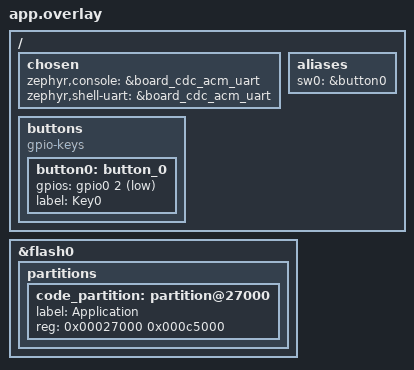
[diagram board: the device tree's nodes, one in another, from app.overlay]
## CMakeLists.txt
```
# Copyright (c) 2026
# SPDX-License-Identifier: MIT
#
# Out-of-tree NCS/Zephyr application for Pro Micro nRF52840 Unifying tests.
# Build from an nRF Connect SDK workspace:
#   west build -b promicro_nrf52840/nrf52840/uf2 <path-to>/examples/promicro_nrf52840

cmake_minimum_required(VERSION 3.20.0)

# Use the SuperMini S140 v7 UF2 + SoftDevice flash map.
set(PM_STATIC_YML_FILE ${CMAKE_CURRENT_SOURCE_DIR}/pm_static.yml CACHE FILEPATH
    "Static partition map for SuperMini S140 v7 UF2" FORCE)

find_package(Zephyr REQUIRED HINTS $ENV{ZEPHYR_BASE})
project(promicro_unifying)

set(UNIFYING_SRC_DIR ${CMAKE_CURRENT_SOURCE_DIR}/../../src)

target_include_directories(app PRIVATE
  ${CMAKE_CURRENT_SOURCE_DIR}/src
  ${UNIFYING_SRC_DIR}
)

target_sources(app PRIVATE
  src/main.c
  src/radio_esb.c
  src/usb_cli.c
  src/persist.c
  src/keymap.c
  src/key_gpio.c
  ${UNIFYING_SRC_DIR}/unifying.c
  ${UNIFYING_SRC_DIR}/unifying_data.c
  ${UNIFYING_SRC_DIR}/unifying_state.c
  ${UNIFYING_SRC_DIR}/unifying_buffer.c
  ${UNIFYING_SRC_DIR}/unifying_utils.c
  ${UNIFYING_SRC_DIR}/unifying_const.c
  ${UNIFYING_SRC_DIR}/unifying_error.c
  ${UNIFYING_SRC_DIR}/aes.c
)
```

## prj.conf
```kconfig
# --- Unifying RF via Nordic ESB (nRF Connect SDK) ---
CONFIG_ESB=y
CONFIG_ESB_MAX_PAYLOAD_LENGTH=32
CONFIG_BT=n

# SuperMini S140 v7 bootloader: emit UF2 and keep the SoftDevice gap
CONFIG_BUILD_OUTPUT_UF2=y
CONFIG_BUILD_OUTPUT_HEX=y

# --- Heap for unifying ring buffers / payloads (malloc) ---
CONFIG_HEAP_MEM_POOL_SIZE=8192
CONFIG_COMMON_LIBC_MALLOC=y

# --- Timing / entropy ---
CONFIG_ENTROPY_GENERATOR=y
CONFIG_PRINTK=y
CONFIG_STDOUT_CONSOLE=y
CONFIG_LOG=y
CONFIG_LOG_DEFAULT_LEVEL=3

# --- GPIO LED ---
CONFIG_GPIO=y

# --- Flash / NVS for pairing credentials ---
CONFIG_FLASH=y
CONFIG_FLASH_MAP=y
CONFIG_FLASH_PAGE_LAYOUT=y
CONFIG_NVS=y
CONFIG_MPU_ALLOW_FLASH_WRITE=y

# --- USB CDC ACM console ---
CONFIG_SERIAL=y
CONFIG_CONSOLE=y
CONFIG_UART_CONSOLE=y
CONFIG_UART_LINE_CTRL=y
CONFIG_USB_DEVICE_STACK_NEXT=y
CONFIG_CDC_ACM_SERIAL_INITIALIZE_AT_BOOT=y
CONFIG_USB_DEVICE_PRODUCT="ProMicro Unifying"
CONFIG_USB_DEVICE_VID=0x1915
CONFIG_USB_DEVICE_PID=0x520F

# Ring buffer for UART RX line assembly
CONFIG_RING_BUFFER=y

# Main stack for pair/connect loops
CONFIG_MAIN_STACK_SIZE=4096
CONFIG_SYSTEM_WORKQUEUE_STACK_SIZE=2048
```

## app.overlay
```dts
/ {
	chosen {
		zephyr,console = &board_cdc_acm_uart;
		zephyr,shell-uart = &board_cdc_acm_uart;
	};

	/*
	 * 测试按键：P0.02 (Pro Micro D19) 对 GND，内部上拉，按下为低有效。
	 * 按下后：休眠则唤醒重连，并发送键 'a'。可按实际矩阵改引脚。
	 */
	buttons {
		compatible = "gpio-keys";
		button0: button_0 {
			gpios = <&gpio0 2 (GPIO_PULL_UP | GPIO_ACTIVE_LOW)>;
			label = "Key0";
		};
	};

	aliases {
		sw0 = &button0;
	};
};

/* SuperMini uses SoftDevice S140 v7.3.0; replace the board's v6 code node. */
&flash0 {
	partitions {
		/delete-node/ partition@26000;

		code_partition: partition@27000 {
			label = "Application";
			reg = <0x00027000 0x000c5000>;
		};
	};
};
```

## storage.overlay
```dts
/*
 * Optional storage partition for boards that lack one in DTS.
 * nRF Connect SDK Partition Manager usually provides storage_partition
 * automatically when CONFIG_NVS=y; this overlay is a fallback for
 * vanilla Zephyr builds of promicro_nrf52840 / nice_nano class boards.
 *
 * If your build already defines storage_partition, west may warn about
 * duplicate labels — remove this file or the partition block in that case.
 */

&flash0 {
	partitions {
		compatible = "fixed-partitions";
		#address-cells = <1>;
		#size-cells = <1>;

		/* Keep bootloader / app layout from board; only ensure a storage label exists.
		 * 8 KiB at end of 1 MiB flash (adjust if your UF2 layout differs).
		 */
		storage_partition: partition@f8000 {
			label = "storage";
			reg = <0x000f8000 0x00008000>;
		};
	};
};
```

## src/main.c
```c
/*!
 * \file main.c
 * \brief Pro Micro nRF52840 Unifying：异步唤醒发键 + USB/RADIO 休眠。
 */

#include <string.h>

#include <zephyr/device.h>
#include <zephyr/drivers/gpio.h>
#include <zephyr/kernel.h>
#include <zephyr/logging/log.h>
#include <zephyr/random/random.h>
#include <zephyr/sys/util.h>

#include "app_ctx.h"
#include "key_gpio.h"
#include "keymap.h"
#include "persist.h"
#include "radio_esb.h"
#include "usb_cli.h"
#include "unifying.h"

LOG_MODULE_REGISTER(main, CONFIG_LOG_DEFAULT_LEVEL);

#define TRANSMIT_BUFFER_SIZE 8
#define RECEIVE_BUFFER_SIZE 8
#define DEVICE_NAME "ProMicroKB"
#define DEVICE_PRODUCT_ID 0x1025
#define DEVICE_SERIAL 0xA58094B6u
#define DEVICE_TYPE 0x0147
#define CAPABILITIES 0x1E40

#define BOOT_PAIR_WINDOW_MS (20 * 1000)
#define IDLE_SLEEP_MS (60 * 1000)
#define BOOT_PAIR_RETRY_MS 2000
#define KEY_RELEASE_GAP_MS 20

#if DT_NODE_HAS_STATUS(DT_ALIAS(led0), okay)
static const struct gpio_dt_spec led = GPIO_DT_SPEC_GET(DT_ALIAS(led0), gpios);
static bool led_ready;
#else
static bool led_ready;
#endif

static struct app_ctx g_ctx;

const char *app_mode_name(enum app_mode mode)
{
	switch (mode) {
	case APP_MODE_IDLE:
		return "idle";
	case APP_MODE_PAIRING:
		return "pairing";
	case APP_MODE_CONNECTED:
		return "connected";
	case APP_MODE_SLEEPING:
		return "sleeping";
	default:
		return "unknown";
	}
}

void app_note_activity(struct app_ctx *ctx)
{
	if (ctx != NULL) {
		ctx->last_activity_ms = k_uptime_get();
	}
}

void app_stop_boot_try(struct app_ctx *ctx)
{
	if (ctx != NULL) {
		ctx->boot_trying = false;
	}
}

void app_start_boot_pair(struct app_ctx *ctx)
{
	if (ctx == NULL) {
		return;
	}

	ctx->boot_trying = true;
	ctx->boot_deadline_ms = k_uptime_get() + BOOT_PAIR_WINDOW_MS;
	ctx->next_boot_attempt_ms = 0;
	LOG_INF("Boot pair window %d ms", BOOT_PAIR_WINDOW_MS);
}

bool app_rf_busy(const struct app_ctx *ctx)
{
	return ctx != NULL && ctx->rf_phase != APP_RF_IDLE;
}

static void led_set(bool on)
{
#if DT_NODE_HAS_STATUS(DT_ALIAS(led0), okay)
	if (!led_ready) {
		return;
	}

	gpio_pin_set_dt(&led, on ? 1 : 0);
#else
	ARG_UNUSED(on);
#endif
}

static void led_init(void)
{
#if DT_NODE_HAS_STATUS(DT_ALIAS(led0), okay)
	if (!device_is_ready(led.port)) {
		LOG_WRN("LED not ready");
		return;
	}

	if (gpio_pin_configure_dt(&led, GPIO_OUTPUT_INACTIVE) != 0) {
		LOG_WRN("LED configure failed");
		return;
	}

	led_ready = true;
#else
	LOG_WRN("No led0 alias");
#endif
}

static uint32_t random_u32(void)
{
	return sys_rand32_get();
}

static void save_credentials(struct app_ctx *ctx)
{
	struct persist_credentials cred;

	memcpy(cred.address, ctx->address, UNIFYING_ADDRESS_LEN);
	memcpy(cred.aes_key, ctx->aes_key, UNIFYING_AES_BLOCK_LEN);
	cred.aes_counter = ctx->aes_counter;
	if (persist_save(&cred) == 0) {
		ctx->has_credentials = true;
	}
}

static void sync_counter_from_state(struct app_ctx *ctx)
{
	ctx->aes_counter = ctx->state.aes_counter;
}

static void state_bind(struct app_ctx *ctx)
{
	unifying_state_init(&ctx->state,
			    &ctx->interface,
			    ctx->transmit_buffer,
			    ctx->receive_buffer,
			    ctx->address,
			    ctx->aes_key,
			    ctx->aes_counter,
			    UNIFYING_DEFAULT_TIMEOUT_KEYBOARD,
			    radio_esb_last_channel());
}

static enum unifying_error rf_prepare_radio(struct app_ctx *ctx)
{
	uint8_t ch;

	if (ctx->usb_suspended) {
		if (usb_cli_resume() != 0) {
			return UNIFYING_ERROR;
		}
		ctx->usb_suspended = false;
	}

	if (radio_esb_is_sleeping()) {
		if (radio_esb_wake() != 0) {
			return UNIFYING_ERROR;
		}
	}

	if (ctx->interface.set_address(ctx->address) != 0) {
		return UNIFYING_SET_ADDRESS_ERROR;
	}

	ch = radio_esb_last_channel();
	if (ctx->interface.set_channel(ch) != 0) {
		return UNIFYING_SET_CHANNEL_ERROR;
	}

	ctx->state.channel = ch;
	unifying_state_buffers_clear(&ctx->state);
	ctx->state.next_transmit = 0;
	ctx->state.previous_transmit = 0;

	LOG_INF("RF start on channel %u (last)", ch);
	return unifying_connect_begin(&ctx->state);
}

static void rf_finish_fail(struct app_ctx *ctx, enum unifying_error err)
{
	ctx->last_error = err;
	ctx->rf_phase = APP_RF_IDLE;
	ctx->key_pending = false;

	if (ctx->boot_connect_pending) {
		ctx->boot_connect_pending = false;
		LOG_WRN("Boot reconnect failed (%s) → pair window",
			unifying_get_error_name(err));
		app_start_boot_pair(ctx);
		return;
	}

	if (ctx->keep_boot_pair_on_fail && ctx->boot_trying) {
		LOG_WRN("Key reconnect failed (%s), continue pairing",
			unifying_get_error_name(err));
		ctx->keep_boot_pair_on_fail = false;
		ctx->mode = APP_MODE_IDLE;
		led_set(false);
		return;
	}

	ctx->keep_boot_pair_on_fail = false;
	ctx->mode = APP_MODE_IDLE;
	led_set(false);
}

static void rf_finish_connected(struct app_ctx *ctx)
{
	ctx->mode = APP_MODE_CONNECTED;
	led_set(true);
	app_note_activity(ctx);
	app_stop_boot_try(ctx);
	ctx->boot_connect_pending = false;
	ctx->keep_boot_pair_on_fail = false;
	ctx->rf_phase = APP_RF_IDLE;
	LOG_INF("Connected (ch=%u)", radio_esb_last_channel());
}

static enum unifying_error rf_start(struct app_ctx *ctx, bool with_key, const char *name)
{
	struct keymap_stroke stroke;

	if (app_rf_busy(ctx)) {
		return UNIFYING_ERROR;
	}

	if (!ctx->has_credentials && ctx->mode != APP_MODE_CONNECTED) {
		return UNIFYING_ERROR;
	}

	ctx->key_pending = with_key;
	ctx->keep_boot_pair_on_fail = ctx->boot_trying;
	ctx->connect_attempts = 0;
	ctx->press_attempts = 0;
	ctx->release_at_ms = 0;

	if (with_key) {
		if (name == NULL || name[0] == '\0') {
			return UNIFYING_ERROR;
		}
		if (!keymap_parse(name, &stroke)) {
			return UNIFYING_ERROR;
		}
		strncpy(ctx->key_name, name, sizeof(ctx->key_name) - 1);
		ctx->key_name[sizeof(ctx->key_name) - 1] = '\0';
		memcpy(ctx->pending_keys, stroke.keys, UNIFYING_KEYS_LEN);
		ctx->pending_modifiers = stroke.modifiers;
	} else {
		ctx->key_name[0] = '\0';
	}

	if (ctx->mode == APP_MODE_CONNECTED && with_key) {
		ctx->rf_phase = APP_RF_SEND_PRESS;
		return UNIFYING_SUCCESS;
	}

	ctx->rf_phase = APP_RF_WAKE_USB_RADIO;
	return UNIFYING_SUCCESS;
}

enum unifying_error app_key_request(struct app_ctx *ctx, const char *name)
{
	return rf_start(ctx, true, name);
}

enum unifying_error app_connect_request(struct app_ctx *ctx)
{
	if (!ctx->has_credentials) {
		return UNIFYING_ERROR;
	}

	return rf_start(ctx, false, NULL);
}

void app_rf_poll(struct app_ctx *ctx)
{
	enum unifying_error err;
	uint8_t release_keys[UNIFYING_KEYS_LEN] = {0};

	if (ctx == NULL || ctx->rf_phase == APP_RF_IDLE) {
		return;
	}

	switch (ctx->rf_phase) {
	case APP_RF_WAKE_USB_RADIO:
		err = rf_prepare_radio(ctx);
		if (err) {
			rf_finish_fail(ctx, err);
			return;
		}
		ctx->rf_phase = APP_RF_CONNECT_TRY;
		return;

	case APP_RF_CONNECT_TRY:
		err = unifying_loop(&ctx->state, true, true, false);
		if (!err) {
			if (ctx->key_pending) {
				ctx->rf_phase = APP_RF_SEND_PRESS;
			} else {
				rf_finish_connected(ctx);
			}
			return;
		}

		ctx->connect_attempts++;
		ctx->last_error = err;
		if (ctx->connect_attempts >= UNIFYING_CHANNELS_LEN) {
			unifying_state_buffers_clear(&ctx->state);
			rf_finish_fail(ctx, err);
			return;
		}
		/* 失败时协议库已 hop，wake 仍在队列，下圈再试 */
		return;

	case APP_RF_SEND_PRESS:
		led_set(true);
		err = unifying_encrypted_keystroke(&ctx->state,
						   ctx->pending_keys,
						   ctx->pending_modifiers);
		if (err == UNIFYING_TRANSMIT_ERROR) {
			ctx->press_attempts++;
			if (ctx->press_attempts >= UNIFYING_CHANNELS_LEN) {
				rf_finish_fail(ctx, err);
			}
			return;
		}
		if (err) {
			rf_finish_fail(ctx, err);
			return;
		}
		sync_counter_from_state(ctx);
		ctx->press_attempts = 0;
		ctx->release_at_ms = k_uptime_get() + KEY_RELEASE_GAP_MS;
		ctx->rf_phase = APP_RF_WAIT_RELEASE;
		ctx->mode = APP_MODE_CONNECTED;
		app_stop_boot_try(ctx);
		ctx->boot_connect_pending = false;
		ctx->keep_boot_pair_on_fail = false;
		return;

	case APP_RF_WAIT_RELEASE:
		if (k_uptime_get() < ctx->release_at_ms) {
			return;
		}
		ctx->rf_phase = APP_RF_SEND_RELEASE;
		ctx->press_attempts = 0;
		return;

	case APP_RF_SEND_RELEASE:
		err = unifying_encrypted_keystroke(&ctx->state, release_keys, 0);
		if (err == UNIFYING_TRANSMIT_ERROR) {
			ctx->press_attempts++;
			if (ctx->press_attempts >= UNIFYING_CHANNELS_LEN) {
				ctx->last_error = err;
				ctx->key_pending = false;
				app_note_activity(ctx);
				ctx->rf_phase = APP_RF_IDLE;
			}
			return;
		}
		if (err) {
			/* 按下已成功；松开失败仍算已连接 */
			ctx->last_error = err;
		} else {
			sync_counter_from_state(ctx);
			ctx->last_error = UNIFYING_SUCCESS;
		}
		ctx->key_pending = false;
		app_note_activity(ctx);
		ctx->rf_phase = APP_RF_IDLE;
		led_set(true);
		return;

	default:
		ctx->rf_phase = APP_RF_IDLE;
		return;
	}
}

enum unifying_error app_do_pair(struct app_ctx *ctx)
{
	enum unifying_error err;
	uint8_t id = (uint8_t)random_u32();
	uint32_t crypto = random_u32();
	const char *name = DEVICE_NAME;
	uint8_t name_length = (uint8_t)strlen(name);

	if (app_rf_busy(ctx)) {
		return UNIFYING_ERROR;
	}

	if (ctx->usb_suspended) {
		(void)usb_cli_resume();
		ctx->usb_suspended = false;
	}

	if (radio_esb_is_sleeping()) {
		if (radio_esb_wake() != 0) {
			return UNIFYING_ERROR;
		}
	}

	ctx->mode = APP_MODE_PAIRING;
	led_set(true);
	unifying_state_buffers_clear(&ctx->state);

	LOG_INF("Pairing as '%s' (len=%u) pid=0x%04x", name, name_length, DEVICE_PRODUCT_ID);

	err = unifying_pair(&ctx->state,
			    id,
			    DEVICE_PRODUCT_ID,
			    DEVICE_TYPE,
			    crypto,
			    DEVICE_SERIAL,
			    CAPABILITIES,
			    name,
			    name_length);
	if (err) {
		ctx->mode = APP_MODE_IDLE;
		led_set(false);
		return err;
	}

	sync_counter_from_state(ctx);
	save_credentials(ctx);
	ctx->mode = APP_MODE_CONNECTED;
	led_set(true);
	app_note_activity(ctx);
	LOG_INF("Paired OK ch=%u", radio_esb_last_channel());
	return UNIFYING_SUCCESS;
}

enum unifying_error app_do_sleep(struct app_ctx *ctx)
{
	app_stop_boot_try(ctx);
	ctx->boot_connect_pending = false;
	ctx->rf_phase = APP_RF_IDLE;
	ctx->key_pending = false;

	/* 休眠前刷一次 counter（平时只改 RAM） */
	if (ctx->has_credentials) {
		sync_counter_from_state(ctx);
		save_credentials(ctx);
	}

	unifying_state_buffers_clear(&ctx->state);
	radio_esb_sleep();

	if (!ctx->usb_suspended) {
		(void)usb_cli_suspend();
		ctx->usb_suspended = true;
	}

	key_gpio_clear_wake();

	ctx->mode = APP_MODE_SLEEPING;
	led_set(false);
	LOG_INF("Sleeping (RADIO+USB off, last_ch=%u)", radio_esb_last_channel());
	return UNIFYING_SUCCESS;
}

enum unifying_error app_do_wake(struct app_ctx *ctx)
{
	app_stop_boot_try(ctx);
	return app_connect_request(ctx);
}

enum unifying_error app_do_unpair(struct app_ctx *ctx)
{
	app_stop_boot_try(ctx);
	ctx->boot_connect_pending = false;
	ctx->rf_phase = APP_RF_IDLE;
	ctx->key_pending = false;
	(void)persist_clear();
	ctx->has_credentials = false;
	memset(ctx->address, 0, sizeof(ctx->address));
	memset(ctx->aes_key, 0, sizeof(ctx->aes_key));
	ctx->aes_counter = random_u32();
	unifying_state_buffers_clear(&ctx->state);

	if (ctx->usb_suspended) {
		(void)usb_cli_resume();
		ctx->usb_suspended = false;
	}

	ctx->mode = APP_MODE_IDLE;
	led_set(false);
	LOG_INF("Unpaired");
	return UNIFYING_SUCCESS;
}

void app_tick(struct app_ctx *ctx)
{
	enum unifying_error err;

	if (ctx->mode != APP_MODE_CONNECTED || app_rf_busy(ctx)) {
		return;
	}

	err = unifying_tick(&ctx->state);
	if (err && err != UNIFYING_TRANSMIT_ERROR) {
		ctx->last_error = err;
	}

	(void)radio_esb_current_channel();
}

void app_power_manage(struct app_ctx *ctx)
{
	int64_t now = k_uptime_get();

	if (app_rf_busy(ctx)) {
		return;
	}

	if (ctx->boot_trying) {
		if (ctx->mode == APP_MODE_CONNECTED) {
			app_stop_boot_try(ctx);
			app_note_activity(ctx);
			return;
		}

		if (now >= ctx->boot_deadline_ms) {
			LOG_WRN("Boot pair window expired → sleep");
			app_stop_boot_try(ctx);
			(void)app_do_sleep(ctx);
			return;
		}

		if (now < ctx->next_boot_attempt_ms) {
			return;
		}

		ctx->next_boot_attempt_ms = now + BOOT_PAIR_RETRY_MS;
		LOG_INF("Boot pair attempt (receiver must be in pairing mode)...");
		ctx->last_error = app_do_pair(ctx);

		if (ctx->mode == APP_MODE_CONNECTED) {
			app_stop_boot_try(ctx);
			app_note_activity(ctx);
		} else if (ctx->last_error) {
			LOG_WRN("Boot pair failed: %s",
				unifying_get_error_name(ctx->last_error));
		}
		return;
	}

	if (ctx->mode == APP_MODE_CONNECTED &&
	    (now - ctx->last_activity_ms) >= IDLE_SLEEP_MS) {
		LOG_INF("No key activity for %d ms → sleep", IDLE_SLEEP_MS);
		(void)app_do_sleep(ctx);
	}
}

int main(void)
{
	struct persist_credentials cred;
	int err;

	led_init();
	LOG_INF("ProMicro Unifying starting");

	err = usb_cli_init();
	if (err) {
		LOG_ERR("usb_cli_init: %d", err);
	}

	err = persist_init();
	if (err) {
		LOG_ERR("persist_init: %d", err);
	}

	err = radio_esb_init(&g_ctx.interface);
	if (err) {
		LOG_ERR("radio_esb_init: %d", err);
	}

	(void)key_gpio_init();

	g_ctx.transmit_buffer = unifying_ring_buffer_create(TRANSMIT_BUFFER_SIZE);
	g_ctx.receive_buffer = unifying_ring_buffer_create(RECEIVE_BUFFER_SIZE);
	if (g_ctx.transmit_buffer == NULL || g_ctx.receive_buffer == NULL) {
		LOG_ERR("ring buffer alloc failed");
		return 0;
	}

	g_ctx.aes_counter = random_u32();
	g_ctx.mode = APP_MODE_IDLE;
	g_ctx.last_error = UNIFYING_SUCCESS;
	g_ctx.last_activity_ms = k_uptime_get();
	g_ctx.rf_phase = APP_RF_IDLE;
	g_ctx.usb_suspended = false;
	g_ctx.boot_connect_pending = false;

	if (persist_load(&cred)) {
		memcpy(g_ctx.address, cred.address, UNIFYING_ADDRESS_LEN);
		memcpy(g_ctx.aes_key, cred.aes_key, UNIFYING_AES_BLOCK_LEN);
		g_ctx.aes_counter = cred.aes_counter;
		g_ctx.has_credentials = true;
		LOG_INF("Loaded credentials from NVS");
	} else {
		memset(g_ctx.address, 0, sizeof(g_ctx.address));
		memset(g_ctx.aes_key, 0, sizeof(g_ctx.aes_key));
		g_ctx.has_credentials = false;
		LOG_INF("No saved credentials");
	}

	state_bind(&g_ctx);

	g_ctx.boot_trying = false;
	if (g_ctx.has_credentials) {
		LOG_INF("Boot reconnect (async, last_ch=%u)...", radio_esb_last_channel());
		g_ctx.boot_connect_pending = true;
		g_ctx.last_error = app_connect_request(&g_ctx);
		if (g_ctx.last_error) {
			g_ctx.boot_connect_pending = false;
			app_start_boot_pair(&g_ctx);
		}
	} else {
		app_start_boot_pair(&g_ctx);
	}

	while (1) {
		if (g_ctx.mode == APP_MODE_SLEEPING && !app_rf_busy(&g_ctx)) {
			key_gpio_wait_wake();
		}

		usb_cli_poll(&g_ctx);
		key_gpio_service(&g_ctx);
		app_rf_poll(&g_ctx);
		app_power_manage(&g_ctx);
		app_tick(&g_ctx);

		if (g_ctx.mode != APP_MODE_SLEEPING || app_rf_busy(&g_ctx)) {
			k_msleep(1);
		}
	}

	return 0;
}
```

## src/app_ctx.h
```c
/*!
 * \file app_ctx.h
 * \brief 应用状态机与共享上下文。
 */

#ifndef APP_CTX_H
#define APP_CTX_H

#include <stdbool.h>
#include <stdint.h>

#include "persist.h"
#include "unifying.h"

#ifdef __cplusplus
extern "C" {
#endif

enum app_mode {
	APP_MODE_IDLE = 0,
	APP_MODE_PAIRING,
	APP_MODE_CONNECTED,
	APP_MODE_SLEEPING,
};

/*! 异步 RF / 发键状态机阶段。 */
enum app_rf_phase {
	APP_RF_IDLE = 0,
	APP_RF_WAKE_USB_RADIO,
	APP_RF_CONNECT_TRY,
	APP_RF_SEND_PRESS,
	APP_RF_WAIT_RELEASE,
	APP_RF_SEND_RELEASE,
};

#define APP_KEY_NAME_MAX 32

struct app_ctx {
	enum app_mode mode;
	bool has_credentials;
	enum unifying_error last_error;
	uint8_t address[UNIFYING_ADDRESS_LEN];
	uint8_t aes_key[UNIFYING_AES_BLOCK_LEN];
	uint32_t aes_counter;
	struct unifying_interface interface;
	struct unifying_ring_buffer *transmit_buffer;
	struct unifying_ring_buffer *receive_buffer;
	struct unifying_state state;

	/*! 上电配对窗口进行中。 */
	bool boot_trying;
	int64_t boot_deadline_ms;
	int64_t next_boot_attempt_ms;
	/*! 上电异步重连进行中。 */
	bool boot_connect_pending;
	/*! 最近一次有效按键活动（用于空闲休眠）。 */
	int64_t last_activity_ms;

	/*! 异步 RF 状态。 */
	enum app_rf_phase rf_phase;
	uint8_t connect_attempts;
	bool key_pending;
	bool keep_boot_pair_on_fail;
	char key_name[APP_KEY_NAME_MAX];
	uint8_t pending_keys[UNIFYING_KEYS_LEN];
	uint8_t pending_modifiers;
	uint8_t press_attempts;
	int64_t release_at_ms;
	bool usb_suspended;
};

/*! 打开上电 20s 自动配对窗口。 */
void app_start_boot_pair(struct app_ctx *ctx);

const char *app_mode_name(enum app_mode mode);

void app_note_activity(struct app_ctx *ctx);
void app_stop_boot_try(struct app_ctx *ctx);
void app_power_manage(struct app_ctx *ctx);

enum unifying_error app_do_pair(struct app_ctx *ctx);
enum unifying_error app_do_sleep(struct app_ctx *ctx);
enum unifying_error app_do_wake(struct app_ctx *ctx);
enum unifying_error app_do_unpair(struct app_ctx *ctx);

/*! 异步：请求发送按键（入队后立即返回）。 */
enum unifying_error app_key_request(struct app_ctx *ctx, const char *name);

/*! 异步：仅请求重连（无按键）。 */
enum unifying_error app_connect_request(struct app_ctx *ctx);

/*! 每圈最多推进一步 RF/发键状态机。 */
void app_rf_poll(struct app_ctx *ctx);

/*! RF 状态机是否忙（勿在忙时进休眠/配对）。 */
bool app_rf_busy(const struct app_ctx *ctx);

void app_tick(struct app_ctx *ctx);

#ifdef __cplusplus
}
#endif

#endif /* APP_CTX_H */
```

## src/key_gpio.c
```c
/*!
 * \file key_gpio.c
 * \brief GPIOTE 中断按键 + 休眠唤醒信号。
 */

#include "key_gpio.h"

#include <zephyr/device.h>
#include <zephyr/drivers/gpio.h>
#include <zephyr/kernel.h>
#include <zephyr/logging/log.h>
#include <zephyr/sys/atomic.h>

LOG_MODULE_REGISTER(key_gpio, CONFIG_LOG_DEFAULT_LEVEL);

K_SEM_DEFINE(key_wake_sem, 0, 1);

#if DT_NODE_HAS_STATUS(DT_ALIAS(sw0), okay)
static const struct gpio_dt_spec key_sw = GPIO_DT_SPEC_GET(DT_ALIAS(sw0), gpios);
static struct gpio_callback key_cb;
static atomic_t key_irq_latched;
static int64_t last_accept_ms;
static bool key_ready;

#define KEY_DEBOUNCE_MS 30
#define KEY_SEND_NAME "a"

static void key_isr(const struct device *port, struct gpio_callback *cb, uint32_t pins)
{
	ARG_UNUSED(port);
	ARG_UNUSED(cb);
	ARG_UNUSED(pins);

	atomic_set(&key_irq_latched, 1);
	k_sem_give(&key_wake_sem);
}
#endif

int key_gpio_init(void)
{
#if DT_NODE_HAS_STATUS(DT_ALIAS(sw0), okay)
	int err;

	if (!gpio_is_ready_dt(&key_sw)) {
		LOG_WRN("sw0 GPIO not ready");
		return -ENODEV;
	}

	err = gpio_pin_configure_dt(&key_sw, GPIO_INPUT);
	if (err) {
		LOG_WRN("sw0 configure failed: %d", err);
		return err;
	}

	err = gpio_pin_interrupt_configure_dt(&key_sw, GPIO_INT_EDGE_TO_ACTIVE);
	if (err) {
		LOG_WRN("sw0 interrupt configure failed: %d", err);
		return err;
	}

	gpio_init_callback(&key_cb, key_isr, BIT(key_sw.pin));
	err = gpio_add_callback(key_sw.port, &key_cb);
	if (err) {
		LOG_WRN("sw0 add callback failed: %d", err);
		return err;
	}

	key_ready = true;
	last_accept_ms = 0;
	atomic_set(&key_irq_latched, 0);
	LOG_INF("Key GPIOTE ready (sw0), press sends '%s'", KEY_SEND_NAME);
	return 0;
#else
	LOG_WRN("No sw0 alias — physical key disabled");
	return 0;
#endif
}

void key_gpio_clear_wake(void)
{
	while (k_sem_take(&key_wake_sem, K_NO_WAIT) == 0) {
	}
}

void key_gpio_wait_wake(void)
{
#if DT_NODE_HAS_STATUS(DT_ALIAS(sw0), okay)
	/* 若 ISR 已锁存，直接返回，避免 clear+take 吞掉信号导致死等 */
	if (atomic_get(&key_irq_latched)) {
		return;
	}
#endif
	(void)k_sem_take(&key_wake_sem, K_FOREVER);
}

void key_gpio_service(struct app_ctx *ctx)
{
#if DT_NODE_HAS_STATUS(DT_ALIAS(sw0), okay)
	int64_t now;
	enum unifying_error err;

	if (!key_ready || ctx == NULL) {
		return;
	}

	if (!atomic_cas(&key_irq_latched, 1, 0)) {
		return;
	}

	now = k_uptime_get();
	if (now - last_accept_ms < KEY_DEBOUNCE_MS) {
		return;
	}

	/* 边沿后确认仍为按下 */
	if (gpio_pin_get_dt(&key_sw) <= 0) {
		return;
	}

	last_accept_ms = now;

	if (ctx->mode != APP_MODE_CONNECTED && !ctx->has_credentials) {
		LOG_INF("Key ignored: not paired");
		return;
	}

	err = app_key_request(ctx, KEY_SEND_NAME);
	ctx->last_error = err;
	if (err) {
		LOG_WRN("Key request failed: %s", unifying_get_error_name(err));
	}
#else
	ARG_UNUSED(ctx);
#endif
}
```

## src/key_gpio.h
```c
/*!
 * \file key_gpio.h
 * \brief GPIOTE 按键：休眠唤醒并异步发键。
 */

#ifndef KEY_GPIO_H
#define KEY_GPIO_H

#include "app_ctx.h"

#ifdef __cplusplus
extern "C" {
#endif

int key_gpio_init(void);

/*! 消费 IRQ pending，入队 app_key_request。 */
void key_gpio_service(struct app_ctx *ctx);

/*! 休眠时阻塞等待 GPIOTE（或任意 give）。 */
void key_gpio_wait_wake(void);

/*! 清空唤醒信号，避免假醒。 */
void key_gpio_clear_wake(void);

#ifdef __cplusplus
}
#endif

#endif /* KEY_GPIO_H */
```

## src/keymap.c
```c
/*!
 * \file keymap.c
 * \brief 常用 HID 键盘 scancode 映射。
 */

#include "keymap.h"

#include <ctype.h>
#include <stdio.h>
#include <string.h>

#include <zephyr/sys/printk.h>
#include <zephyr/sys/util.h>

struct named_key {
	const char *name;
	uint8_t scancode;
};

/* USB HID Usage Tables - Keyboard/Keypad */
static const struct named_key named_keys[] = {
	{"enter", 0x28},
	{"esc", 0x29},
	{"escape", 0x29},
	{"bspc", 0x2A},
	{"backspace", 0x2A},
	{"tab", 0x2B},
	{"space", 0x2C},
	{"minus", 0x2D},
	{"equal", 0x2E},
	{"lbrace", 0x2F},
	{"rbrace", 0x30},
	{"bslash", 0x31},
	{"semi", 0x33},
	{"quote", 0x34},
	{"grave", 0x35},
	{"comma", 0x36},
	{"dot", 0x37},
	{"slash", 0x38},
	{"caps", 0x39},
	{"f1", 0x3A},
	{"f2", 0x3B},
	{"f3", 0x3C},
	{"f4", 0x3D},
	{"f5", 0x3E},
	{"f6", 0x3F},
	{"f7", 0x40},
	{"f8", 0x41},
	{"f9", 0x42},
	{"f10", 0x43},
	{"f11", 0x44},
	{"f12", 0x45},
	{"right", 0x4F},
	{"left", 0x50},
	{"down", 0x51},
	{"up", 0x52},
};

static uint8_t modifier_from_name(const char *name)
{
	if (strcmp(name, "ctrl") == 0 || strcmp(name, "lctrl") == 0) {
		return 0x01;
	}
	if (strcmp(name, "rctrl") == 0) {
		return 0x10;
	}
	if (strcmp(name, "shift") == 0 || strcmp(name, "lshift") == 0) {
		return 0x02;
	}
	if (strcmp(name, "rshift") == 0) {
		return 0x20;
	}
	if (strcmp(name, "alt") == 0 || strcmp(name, "lalt") == 0) {
		return 0x04;
	}
	if (strcmp(name, "ralt") == 0 || strcmp(name, "altgr") == 0) {
		return 0x40;
	}
	if (strcmp(name, "gui") == 0 || strcmp(name, "win") == 0 || strcmp(name, "meta") == 0) {
		return 0x08;
	}
	return 0;
}

static bool scancode_from_token(const char *token, uint8_t *scancode)
{
	size_t i;

	if (token[0] != '\0' && token[1] == '\0') {
		char c = (char)tolower((unsigned char)token[0]);

		if (c >= 'a' && c <= 'z') {
			*scancode = (uint8_t)(0x04 + (c - 'a'));
			return true;
		}
		if (c >= '1' && c <= '9') {
			*scancode = (uint8_t)(0x1E + (c - '1'));
			return true;
		}
		if (c == '0') {
			*scancode = 0x27;
			return true;
		}
	}

	for (i = 0; i < ARRAY_SIZE(named_keys); i++) {
		if (strcmp(token, named_keys[i].name) == 0) {
			*scancode = named_keys[i].scancode;
			return true;
		}
	}

	return false;
}

bool keymap_parse(const char *name, struct keymap_stroke *out)
{
	char buf[48];
	char token[24];
	size_t i = 0;
	size_t t = 0;
	uint8_t key_index = 0;
	bool have_key = false;

	if (name == NULL || out == NULL || name[0] == '\0') {
		return false;
	}

	if (strlen(name) >= sizeof(buf)) {
		return false;
	}

	memset(out, 0, sizeof(*out));

	for (i = 0; name[i] != '\0'; i++) {
		buf[i] = (char)tolower((unsigned char)name[i]);
	}
	buf[i] = '\0';

	i = 0;
	while (true) {
		char c = buf[i];

		if (c != '+' && c != '\0') {
			if (t + 1 < sizeof(token)) {
				token[t++] = c;
			}
			i++;
			continue;
		}

		token[t] = '\0';
		if (t > 0) {
			uint8_t mod = modifier_from_name(token);
			uint8_t scancode = 0;

			if (mod != 0) {
				out->modifiers |= mod;
			} else if (scancode_from_token(token, &scancode)) {
				if (key_index >= UNIFYING_KEYS_LEN) {
					return false;
				}
				out->keys[UNIFYING_KEYS_LEN - 1 - key_index] = scancode;
				key_index++;
				have_key = true;
			} else {
				return false;
			}
		}

		if (c == '\0') {
			break;
		}

		t = 0;
		i++;
	}

	return have_key || out->modifiers != 0;
}

void keymap_print_help(void)
{
	printk("keys: a-z 0-9 enter esc space tab bspc\n");
	printk("      f1-f12 left right up down\n");
	printk("mods: shift+a  ctrl+c  alt+tab  gui+e\n");
}
```

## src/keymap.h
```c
/*!
 * \file keymap.h
 * \brief 按键名称到 HID scancode / modifier 的映射。
 */

#ifndef KEYMAP_H
#define KEYMAP_H

#include <stdbool.h>
#include <stdint.h>

#include "unifying_const.h"

#ifdef __cplusplus
extern "C" {
#endif

struct keymap_stroke {
	uint8_t modifiers;
	uint8_t keys[UNIFYING_KEYS_LEN];
};

/*!
 * 解析按键名（如 "a"、"enter"、"shift+a"、"ctrl+c"）。
 *
 * \return true 解析成功。
 */
bool keymap_parse(const char *name, struct keymap_stroke *out);

/*!
 * 打印支持的按键列表到控制台。
 */
void keymap_print_help(void);

#ifdef __cplusplus
}
#endif

#endif /* KEYMAP_H */
```

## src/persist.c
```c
/*!
 * \file persist.c
 * \brief NVS 存储 Unifying 地址与 AES 密钥。
 */

#include "persist.h"

#include <string.h>

#include <zephyr/drivers/flash.h>
#include <zephyr/fs/nvs.h>
#include <zephyr/logging/log.h>
#include <zephyr/storage/flash_map.h>

LOG_MODULE_REGISTER(persist, CONFIG_LOG_DEFAULT_LEVEL);

#define NVS_PARTITION storage_partition
#define NVS_PARTITION_DEVICE FIXED_PARTITION_DEVICE(NVS_PARTITION)
#define NVS_PARTITION_OFFSET FIXED_PARTITION_OFFSET(NVS_PARTITION)

#define NVS_ID_CREDENTIALS 1
#define PERSIST_MAGIC 0x554E4901u /* 'UNI' + 1 */

struct persist_blob {
	uint32_t magic;
	uint8_t address[UNIFYING_ADDRESS_LEN];
	uint8_t aes_key[UNIFYING_AES_BLOCK_LEN];
	uint32_t aes_counter;
};

static struct nvs_fs fs;
static bool ready;

int persist_init(void)
{
	struct flash_pages_info info;
	int err;

	fs.flash_device = NVS_PARTITION_DEVICE;
	if (!device_is_ready(fs.flash_device)) {
		LOG_ERR("Flash device not ready");
		return -ENODEV;
	}

	fs.offset = NVS_PARTITION_OFFSET;
	err = flash_get_page_info_by_offs(fs.flash_device, fs.offset, &info);
	if (err) {
		LOG_ERR("flash_get_page_info_by_offs: %d", err);
		return err;
	}

	fs.sector_size = info.size;
	fs.sector_count = 2U;

	err = nvs_mount(&fs);
	if (err) {
		LOG_ERR("nvs_mount: %d", err);
		return err;
	}

	ready = true;
	LOG_INF("NVS ready");
	return 0;
}

bool persist_load(struct persist_credentials *out)
{
	struct persist_blob blob;
	ssize_t rc;

	if (!ready || out == NULL) {
		return false;
	}

	rc = nvs_read(&fs, NVS_ID_CREDENTIALS, &blob, sizeof(blob));
	if (rc != (ssize_t)sizeof(blob)) {
		return false;
	}

	if (blob.magic != PERSIST_MAGIC) {
		return false;
	}

	memcpy(out->address, blob.address, UNIFYING_ADDRESS_LEN);
	memcpy(out->aes_key, blob.aes_key, UNIFYING_AES_BLOCK_LEN);
	out->aes_counter = blob.aes_counter;
	return true;
}

int persist_save(const struct persist_credentials *in)
{
	struct persist_blob blob;
	int err;

	if (!ready || in == NULL) {
		return -EINVAL;
	}

	memset(&blob, 0, sizeof(blob));
	blob.magic = PERSIST_MAGIC;
	memcpy(blob.address, in->address, UNIFYING_ADDRESS_LEN);
	memcpy(blob.aes_key, in->aes_key, UNIFYING_AES_BLOCK_LEN);
	blob.aes_counter = in->aes_counter;

	err = nvs_write(&fs, NVS_ID_CREDENTIALS, &blob, sizeof(blob));
	if (err < 0) {
		LOG_ERR("nvs_write: %d", err);
		return err;
	}

	return 0;
}

int persist_clear(void)
{
	int err;

	if (!ready) {
		return -EINVAL;
	}

	err = nvs_delete(&fs, NVS_ID_CREDENTIALS);
	if (err && err != -ENOENT) {
		LOG_ERR("nvs_delete: %d", err);
		return err;
	}

	return 0;
}
```

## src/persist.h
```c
/*!
 * \file persist.h
 * \brief 使用 NVS 保存 / 读取 Unifying 配对凭证。
 */

#ifndef PERSIST_H
#define PERSIST_H

#include <stdbool.h>
#include <stdint.h>

#include "unifying_const.h"

#ifdef __cplusplus
extern "C" {
#endif

struct persist_credentials {
	uint8_t address[UNIFYING_ADDRESS_LEN];
	uint8_t aes_key[UNIFYING_AES_BLOCK_LEN];
	uint32_t aes_counter;
};

/*!
 * 初始化 NVS。
 *
 * \return 0 成功，负值失败。
 */
int persist_init(void);

/*!
 * 从 NVS 加载凭证。
 *
 * \return true 若存在有效凭证。
 */
bool persist_load(struct persist_credentials *out);

/*!
 * 保存凭证到 NVS。
 *
 * \return 0 成功，负值失败。
 */
int persist_save(const struct persist_credentials *in);

/*!
 * 清除已保存的凭证。
 *
 * \return 0 成功，负值失败。
 */
int persist_clear(void);

#ifdef __cplusplus
}
#endif

#endif /* PERSIST_H */
```

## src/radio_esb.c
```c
/*!
 * \file radio_esb.c
 * \brief Nordic ESB PTX 适配，对接 unifying_interface。
 */

#include "radio_esb.h"

#include <errno.h>
#include <string.h>

#include <zephyr/kernel.h>
#include <zephyr/logging/log.h>
#include <zephyr/sys/atomic.h>
#include <zephyr/sys/util.h>

#include <esb.h>

#include "unifying_utils.h"

LOG_MODULE_REGISTER(radio_esb, CONFIG_LOG_DEFAULT_LEVEL);

#ifndef CONFIG_ESB_MAX_PAYLOAD_LENGTH
#define CONFIG_ESB_MAX_PAYLOAD_LENGTH 32
#endif

#define RADIO_RX_QUEUE_DEPTH 4
#define RADIO_TX_TIMEOUT_MS 150

struct radio_rx_slot {
	uint8_t length;
	uint8_t data[UNIFYING_MAX_PAYLOAD_LEN];
};

static struct k_sem tx_done_sem;
static struct k_mutex radio_mutex;

static volatile bool tx_ok;
static atomic_t sleeping;
static bool esb_ready;

static uint8_t last_address_msb[UNIFYING_ADDRESS_LEN];
static uint8_t last_channel;
static bool have_address;

static struct radio_rx_slot rx_queue[RADIO_RX_QUEUE_DEPTH];
static uint8_t rx_head;
static uint8_t rx_tail;
static uint8_t rx_count;
static uint8_t last_rx_size;

static void rx_queue_clear(void)
{
	rx_head = 0;
	rx_tail = 0;
	rx_count = 0;
	last_rx_size = 0;
}

static void rx_queue_push(const uint8_t *data, uint8_t length)
{
	if (length == 0 || length > UNIFYING_MAX_PAYLOAD_LEN) {
		return;
	}

	if (rx_count >= RADIO_RX_QUEUE_DEPTH) {
		/* 丢弃最旧的 ACK，为新数据腾出空间 */
		rx_head = (rx_head + 1) % RADIO_RX_QUEUE_DEPTH;
		rx_count--;
	}

	struct radio_rx_slot *slot = &rx_queue[rx_tail];

	slot->length = length;
	memcpy(slot->data, data, length);
	rx_tail = (rx_tail + 1) % RADIO_RX_QUEUE_DEPTH;
	rx_count++;
	last_rx_size = length;
}

static void drain_esb_rx(void)
{
	struct esb_payload rx;

	while (esb_read_rx_payload(&rx) == 0) {
		rx_queue_push(rx.data, rx.length);
	}
}

static void radio_esb_event_handler(const struct esb_evt *event)
{
	switch (event->evt_id) {
	case ESB_EVENT_TX_SUCCESS:
		tx_ok = true;
		drain_esb_rx();
		k_sem_give(&tx_done_sem);
		break;
	case ESB_EVENT_TX_FAILED:
		tx_ok = false;
		esb_flush_tx();
		k_sem_give(&tx_done_sem);
		break;
	case ESB_EVENT_RX_RECEIVED:
		drain_esb_rx();
		break;
	default:
		break;
	}
}

static int apply_address_msb(const uint8_t address_msb[UNIFYING_ADDRESS_LEN])
{
	uint8_t address_lsb[UNIFYING_ADDRESS_LEN];
	uint8_t base_addr[4];
	uint8_t prefix[1];
	int err;

	/* 库内地址为 MSB first；nRF/ESB 使用 LSB first。 */
	unifying_copy_reverse(address_lsb, address_msb, UNIFYING_ADDRESS_LEN);

	/* pipe0 地址 = prefix(1) + base(4)，prefix 为 on-air 最低字节。 */
	prefix[0] = address_lsb[0];
	memcpy(base_addr, &address_lsb[1], sizeof(base_addr));

	err = esb_set_base_address_0(base_addr);
	if (err) {
		return err;
	}

	err = esb_set_prefixes(prefix, 1);
	if (err) {
		return err;
	}

	err = esb_enable_pipes(BIT(0));
	if (err) {
		return err;
	}

	memcpy(last_address_msb, address_msb, UNIFYING_ADDRESS_LEN);
	have_address = true;
	return 0;
}

static int esb_configure(void)
{
	struct esb_config config = ESB_DEFAULT_CONFIG;
	int err;

	config.protocol = ESB_PROTOCOL_ESB_DPL;
	config.mode = ESB_MODE_PTX;
	config.event_handler = radio_esb_event_handler;
	config.bitrate = ESB_BITRATE_2MBPS;
	config.crc = ESB_CRC_16BIT;
	config.tx_output_power = 4; /* ~+4 dBm，接近 RF24 PA_MAX */
	config.retransmit_delay = 3750; /* 对齐 RF24 setRetries(15, *) 的 15*250us */
	config.retransmit_count = 15;   /* 提高抗干扰，减轻偶发 TRANSMIT_ERROR */
	config.tx_mode = ESB_TXMODE_AUTO;
	config.payload_length = UNIFYING_MAX_PAYLOAD_LEN;
	config.selective_auto_ack = false;
	config.use_fast_ramp_up = false;

	err = esb_init(&config);
	if (err) {
		LOG_ERR("esb_init failed: %d", err);
		return err;
	}

	err = esb_set_address_length(UNIFYING_ADDRESS_LEN);
	if (err) {
		LOG_ERR("esb_set_address_length failed: %d", err);
		return err;
	}

	esb_ready = true;
	atomic_set(&sleeping, 0);
	return 0;
}

static uint8_t radio_transmit_payload(const uint8_t *payload, uint8_t length)
{
	struct esb_payload tx = {0};
	int err;

	if (atomic_get(&sleeping) || !esb_ready) {
		return 1;
	}

	if (payload == NULL || length == 0 || length > CONFIG_ESB_MAX_PAYLOAD_LENGTH) {
		return 1;
	}

	k_mutex_lock(&radio_mutex, K_FOREVER);

	while (k_sem_take(&tx_done_sem, K_NO_WAIT) == 0) {
		/* 清空残留信号 */
	}

	tx.pipe = 0;
	tx.length = length;
	tx.noack = false;
	memcpy(tx.data, payload, length);

	err = esb_write_payload(&tx);
	if (err) {
		LOG_WRN("esb_write_payload failed: %d", err);
		k_mutex_unlock(&radio_mutex);
		return 1;
	}

	err = k_sem_take(&tx_done_sem, K_MSEC(RADIO_TX_TIMEOUT_MS));
	if (err) {
		LOG_WRN("TX timeout");
		esb_flush_tx();
		k_mutex_unlock(&radio_mutex);
		return 1;
	}

	k_mutex_unlock(&radio_mutex);
	return tx_ok ? 0 : 1;
}

static uint8_t radio_receive_payload(uint8_t *payload, uint8_t length)
{
	uint8_t copy_len;

	if (payload == NULL || length == 0 || rx_count == 0) {
		return 0;
	}

	k_mutex_lock(&radio_mutex, K_FOREVER);

	if (rx_count == 0) {
		k_mutex_unlock(&radio_mutex);
		return 0;
	}

	struct radio_rx_slot *slot = &rx_queue[rx_head];

	copy_len = slot->length < length ? slot->length : length;
	memcpy(payload, slot->data, copy_len);
	last_rx_size = slot->length;

	rx_head = (rx_head + 1) % RADIO_RX_QUEUE_DEPTH;
	rx_count--;

	k_mutex_unlock(&radio_mutex);
	return copy_len;
}

static bool radio_payload_available(void)
{
	return rx_count > 0;
}

static uint8_t radio_payload_size(void)
{
	if (rx_count == 0) {
		return 0;
	}

	return rx_queue[rx_head].length;
}

static uint8_t radio_set_address(const uint8_t address[UNIFYING_ADDRESS_LEN])
{
	int err;

	if (atomic_get(&sleeping) || !esb_ready) {
		memcpy(last_address_msb, address, UNIFYING_ADDRESS_LEN);
		have_address = true;
		return 1;
	}

	k_mutex_lock(&radio_mutex, K_FOREVER);
	err = apply_address_msb(address);
	k_mutex_unlock(&radio_mutex);

	if (err) {
		LOG_ERR("set_address failed: %d", err);
		return 1;
	}

	LOG_INF("RF address set");
	return 0;
}

static uint8_t radio_set_channel(uint8_t channel)
{
	int err;

	last_channel = channel;

	if (atomic_get(&sleeping) || !esb_ready) {
		return 1;
	}

	k_mutex_lock(&radio_mutex, K_FOREVER);
	err = esb_set_rf_channel(channel);
	k_mutex_unlock(&radio_mutex);

	if (err) {
		LOG_ERR("set_channel %u failed: %d", channel, err);
		return 1;
	}

	LOG_DBG("RF channel %u", channel);
	return 0;
}

static uint32_t radio_time(void)
{
	return k_uptime_get_32();
}

int radio_esb_init(struct unifying_interface *interface)
{
	int err;

	if (interface == NULL) {
		return -EINVAL;
	}

	k_sem_init(&tx_done_sem, 0, 1);
	k_mutex_init(&radio_mutex);
	rx_queue_clear();
	have_address = false;
	last_channel = unifying_channels[0];
	atomic_set(&sleeping, 0);
	esb_ready = false;

	err = esb_configure();
	if (err) {
		return err;
	}

	err = esb_set_rf_channel(last_channel);
	if (err) {
		LOG_ERR("initial channel failed: %d", err);
		return err;
	}

	err = unifying_interface_init(interface,
					 radio_transmit_payload,
					 radio_receive_payload,
					 radio_payload_available,
					 radio_payload_size,
					 radio_set_address,
					 radio_set_channel,
					 radio_time,
					 NULL);
	if (err != UNIFYING_SUCCESS) {
		return -EIO;
	}

	LOG_INF("ESB radio ready");
	return 0;
}

void radio_esb_sleep(void)
{
	k_mutex_lock(&radio_mutex, K_FOREVER);

	if (esb_ready) {
		esb_disable();
		esb_ready = false;
	}

	rx_queue_clear();
	atomic_set(&sleeping, 1);
	k_mutex_unlock(&radio_mutex);
	LOG_INF("RADIO sleeping");
}

int radio_esb_wake(void)
{
	int err;

	k_mutex_lock(&radio_mutex, K_FOREVER);

	rx_queue_clear();
	err = esb_configure();
	if (err) {
		k_mutex_unlock(&radio_mutex);
		return err;
	}

	err = esb_set_rf_channel(last_channel);
	if (err) {
		k_mutex_unlock(&radio_mutex);
		return err;
	}

	if (have_address) {
		err = apply_address_msb(last_address_msb);
		if (err) {
			k_mutex_unlock(&radio_mutex);
			return err;
		}
	}

	atomic_set(&sleeping, 0);
	k_mutex_unlock(&radio_mutex);
	LOG_INF("RADIO awake, channel %u", last_channel);
	return 0;
}

bool radio_esb_is_sleeping(void)
{
	return atomic_get(&sleeping) != 0;
}

uint8_t radio_esb_current_channel(void)
{
	return last_channel;
}

uint8_t radio_esb_last_channel(void)
{
	return last_channel;
}
```

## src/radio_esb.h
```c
/*!
 * \file radio_esb.h
 * \brief Nordic ESB 适配层，实现 unifying_interface 射频回调。
 */

#ifndef RADIO_ESB_H
#define RADIO_ESB_H

#include <stdbool.h>
#include <stdint.h>

#include "unifying.h"

#ifdef __cplusplus
extern "C" {
#endif

/*!
 * 初始化 ESB PTX，并填充 unifying_interface 中的射频相关回调。
 * encrypt 回调保持为 NULL（使用库内置 tiny-AES）。
 *
 * \return 0 成功，负值失败。
 */
int radio_esb_init(struct unifying_interface *interface);

/*!
 * 关闭 RADIO（主动休眠）。
 */
void radio_esb_sleep(void);

/*!
 * 从休眠恢复 RADIO，并还原最近一次地址与信道。
 *
 * \return 0 成功，负值失败。
 */
int radio_esb_wake(void);

/*!
 * 当前是否处于休眠（RADIO 关闭）。
 */
bool radio_esb_is_sleeping(void);

/*!
 * 最近一次设置的 RF 信道（Unifying 信道号，休眠后仍保留在 RAM）。
 */
uint8_t radio_esb_current_channel(void);

/*!
 * 上次使用的信道（RAM）；等同 current，语义上供唤醒优先使用。
 */
uint8_t radio_esb_last_channel(void);

#ifdef __cplusplus
}
#endif

#endif /* RADIO_ESB_H */
```

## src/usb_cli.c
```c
/*!
 * \file usb_cli.c
 * \brief USB CDC 文本命令处理。
 */

#include "usb_cli.h"

#include <ctype.h>
#include <stdio.h>
#include <string.h>

#include <zephyr/device.h>
#include <zephyr/drivers/uart.h>
#include <zephyr/kernel.h>
#include <zephyr/logging/log.h>
#include <zephyr/sys/ring_buffer.h>
#include <zephyr/usb/usb_device.h>

#if defined(CONFIG_USB_DEVICE_STACK_NEXT)
#include <zephyr/drivers/usb/udc.h>
#endif

#include "app_ctx.h"
#include "keymap.h"
#include "radio_esb.h"
#include "unifying_error.h"

LOG_MODULE_REGISTER(usb_cli, CONFIG_LOG_DEFAULT_LEVEL);

#define LINE_MAX 64
#define RX_RING_SIZE 256

static const struct device *cdc_dev;
#if defined(CONFIG_USB_DEVICE_STACK_NEXT)
static const struct device *udc_dev;
#endif
static struct ring_buf rx_ring;
static uint8_t rx_ring_data[RX_RING_SIZE];
static char line_buf[LINE_MAX];
static size_t line_len;
static bool irq_enabled;
static bool banner_shown;
static bool usb_suspended;

static void print_help(void)
{
	printk("Commands:\n");
	printk("  help              show this help\n");
	printk("  status            show connection state\n");
	printk("  pair              pair with Unifying receiver\n");
	printk("  sleep             RADIO+USB sleep (GPIOTE wake)\n");
	printk("  wake              async wake-up and reconnect\n");
	printk("  key <name>        queue key press+release\n");
	printk("  unpair            erase credentials\n");
	keymap_print_help();
}

static void print_status(struct app_ctx *ctx)
{
	printk("mode=%s paired=%s channel=%u last_err=%s (%d)\n",
	       app_mode_name(ctx->mode),
	       ctx->has_credentials ? "yes" : "no",
	       radio_esb_current_channel(),
	       unifying_get_error_name(ctx->last_error),
	       (int)ctx->last_error);
}

static void reply_ok(void)
{
	printk("OK\n");
}

static void reply_err(const char *msg, enum unifying_error err)
{
	if (err != UNIFYING_SUCCESS) {
		printk("ERR %s (%s)\n", msg, unifying_get_error_name(err));
	} else {
		printk("ERR %s\n", msg);
	}
}

static void trim_inplace(char *s)
{
	size_t n;
	char *start = s;

	while (*start != '\0' && isspace((unsigned char)*start)) {
		start++;
	}

	if (start != s) {
		memmove(s, start, strlen(start) + 1);
	}

	n = strlen(s);
	while (n > 0 && isspace((unsigned char)s[n - 1])) {
		s[n - 1] = '\0';
		n--;
	}
}

static void handle_line(struct app_ctx *ctx, char *line)
{
	enum unifying_error err;

	trim_inplace(line);
	if (line[0] == '\0') {
		return;
	}

	if (strcmp(line, "help") == 0 || strcmp(line, "?") == 0) {
		print_help();
		reply_ok();
		return;
	}

	if (strcmp(line, "status") == 0) {
		print_status(ctx);
		reply_ok();
		return;
	}

	if (strcmp(line, "pair") == 0) {
		app_stop_boot_try(ctx);
		printk("Pairing... put receiver in pairing mode first.\n");
		err = app_do_pair(ctx);
		ctx->last_error = err;
		if (err) {
			reply_err("pair_failed", err);
		} else {
			reply_ok();
		}
		return;
	}

	if (strcmp(line, "sleep") == 0) {
		err = app_do_sleep(ctx);
		ctx->last_error = err;
		if (err) {
			reply_err("sleep_failed", err);
		} else {
			reply_ok();
		}
		return;
	}

	if (strcmp(line, "wake") == 0) {
		err = app_do_wake(ctx);
		ctx->last_error = err;
		if (err) {
			reply_err("wake_failed", err);
		} else {
			printk("Wake queued\n");
			reply_ok();
		}
		return;
	}

	if (strncmp(line, "key ", 4) == 0) {
		err = app_key_request(ctx, line + 4);
		ctx->last_error = err;
		if (err == UNIFYING_ERROR) {
			if (!ctx->has_credentials && ctx->mode != APP_MODE_CONNECTED) {
				reply_err("not_paired", UNIFYING_SUCCESS);
			} else if (app_rf_busy(ctx)) {
				reply_err("busy", UNIFYING_SUCCESS);
			} else {
				reply_err("unknown_key", UNIFYING_SUCCESS);
			}
		} else if (err) {
			reply_err("key_failed", err);
		} else {
			reply_ok();
		}
		return;
	}

	if (strcmp(line, "unpair") == 0) {
		err = app_do_unpair(ctx);
		ctx->last_error = err;
		if (err) {
			reply_err("unpair_failed", err);
		} else {
			reply_ok();
		}
		return;
	}

	reply_err("unknown_cmd", UNIFYING_SUCCESS);
}

static void cdc_interrupt_handler(const struct device *dev, void *user_data)
{
	uint8_t tmp[64];
	int rx;

	ARG_UNUSED(user_data);

	while (uart_irq_update(dev) && uart_irq_is_pending(dev)) {
		if (!uart_irq_rx_ready(dev)) {
			continue;
		}

		rx = uart_fifo_read(dev, tmp, sizeof(tmp));
		if (rx > 0) {
			ring_buf_put(&rx_ring, tmp, rx);
		}
	}
}

static void try_show_banner(struct app_ctx *ctx)
{
	uint32_t dtr = 0;

	if (banner_shown || cdc_dev == NULL) {
		return;
	}

	(void)uart_line_ctrl_get(cdc_dev, UART_LINE_CTRL_DTR, &dtr);
	if (!dtr) {
		return;
	}

	(void)uart_line_ctrl_set(cdc_dev, UART_LINE_CTRL_DCD, 1);
	(void)uart_line_ctrl_set(cdc_dev, UART_LINE_CTRL_DSR, 1);

	if (!irq_enabled) {
		uart_irq_callback_set(cdc_dev, cdc_interrupt_handler);
		uart_irq_rx_enable(cdc_dev);
		irq_enabled = true;
	}

	printk("\n=== ProMicro Unifying CLI ===\n");
	printk("Type 'help' for commands.\n");
	printk("Boot status: mode=%s paired=%s last_err=%s\n",
	       app_mode_name(ctx->mode),
	       ctx->has_credentials ? "yes" : "no",
	       unifying_get_error_name(ctx->last_error));
	banner_shown = true;
}

int usb_cli_init(void)
{
	int err;

	cdc_dev = DEVICE_DT_GET(DT_CHOSEN(zephyr_console));
	if (!device_is_ready(cdc_dev)) {
		LOG_ERR("CDC ACM not ready");
		return -ENODEV;
	}

#if defined(CONFIG_USB_DEVICE_STACK_NEXT)
	udc_dev = DEVICE_DT_GET(DT_NODELABEL(zephyr_udc0));
	if (!device_is_ready(udc_dev)) {
		LOG_WRN("zephyr_udc0 not ready — USB suspend may fail");
		udc_dev = NULL;
	}
#endif

	ring_buf_init(&rx_ring, sizeof(rx_ring_data), rx_ring_data);
	usb_suspended = false;
	banner_shown = false;
	irq_enabled = false;

#if defined(CONFIG_USB_DEVICE_STACK) && !defined(CONFIG_USB_DEVICE_INITIALIZE_AT_BOOT)
	err = usb_enable(NULL);
	if (err && err != -EALREADY) {
		LOG_ERR("usb_enable: %d", err);
		return err;
	}
#else
	ARG_UNUSED(err);
#endif

	LOG_INF("USB CLI ready (open serial port to interact)");
	return 0;
}

int usb_cli_suspend(void)
{
	int err = 0;

	if (usb_suspended) {
		return 0;
	}

	irq_enabled = false;
	banner_shown = false;
	line_len = 0;
	ring_buf_reset(&rx_ring);

#if defined(CONFIG_USB_DEVICE_STACK_NEXT)
	if (udc_dev != NULL) {
		err = udc_disable(udc_dev);
		if (err && err != -EALREADY) {
			LOG_WRN("udc_disable: %d", err);
		}
	}
#else
	err = usb_disable();
	if (err && err != -EALREADY) {
		LOG_WRN("usb_disable: %d", err);
	}
#endif

	usb_suspended = true;
	LOG_INF("USB suspended");
	return 0;
}

int usb_cli_resume(void)
{
	int err = 0;

	if (!usb_suspended) {
		return 0;
	}

#if defined(CONFIG_USB_DEVICE_STACK_NEXT)
	if (udc_dev != NULL) {
		err = udc_enable(udc_dev);
		if (err && err != -EALREADY) {
			LOG_ERR("udc_enable: %d", err);
			return err;
		}
	}
#else
	err = usb_enable(NULL);
	if (err && err != -EALREADY) {
		LOG_ERR("usb_enable resume: %d", err);
		return err;
	}
#endif

	usb_suspended = false;
	banner_shown = false;
	irq_enabled = false;
	LOG_INF("USB resumed");
	return 0;
}

bool usb_cli_is_suspended(void)
{
	return usb_suspended;
}

void usb_cli_poll(struct app_ctx *ctx)
{
	uint8_t byte;

	if (usb_suspended) {
		return;
	}

	try_show_banner(ctx);

	if (!banner_shown) {
		return;
	}

	while (ring_buf_get(&rx_ring, &byte, 1) == 1) {
		if (byte == '\r') {
			continue;
		}

		if (byte == '\n') {
			line_buf[line_len] = '\0';
			handle_line(ctx, line_buf);
			line_len = 0;
			continue;
		}

		if (line_len + 1 < LINE_MAX) {
			line_buf[line_len++] = (char)byte;
		} else {
			line_len = 0;
			reply_err("line_too_long", UNIFYING_SUCCESS);
		}
	}
}
```

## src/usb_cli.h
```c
/*!
 * \file usb_cli.h
 * \brief USB CDC 文本命令行。
 */

#ifndef USB_CLI_H
#define USB_CLI_H

#include <stdbool.h>

#ifdef __cplusplus
extern "C" {
#endif

struct app_ctx;

int usb_cli_init(void);

/*! 休眠时禁用 USB。 */
int usb_cli_suspend(void);

/*! 唤醒后重新使能 USB（需重新打开串口）。 */
int usb_cli_resume(void);

bool usb_cli_is_suspended(void);

void usb_cli_poll(struct app_ctx *ctx);

#ifdef __cplusplus
}
#endif

#endif /* USB_CLI_H */
```
